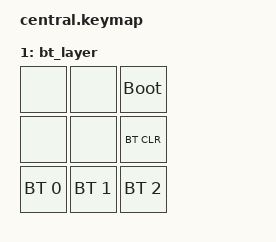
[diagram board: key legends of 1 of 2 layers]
#include <behaviors.dtsi>
#include <dt-bindings/zmk/keys.h>
#include <dt-bindings/zmk/bt.h>

/ {
    keymap {
        compatible = "zmk,keymap";
        default_layer {
            bindings = <
                &kp A         &mo 1
                &kp C         &kp D
            >;
        };

        bt_layer {
            bindings = <
                &none &none &bootloader
                &none &none &bt BT_CLR
                &bt BT_SEL 0 &bt BT_SEL 1 &bt BT_SEL 2
            >;
        };
    };
};
